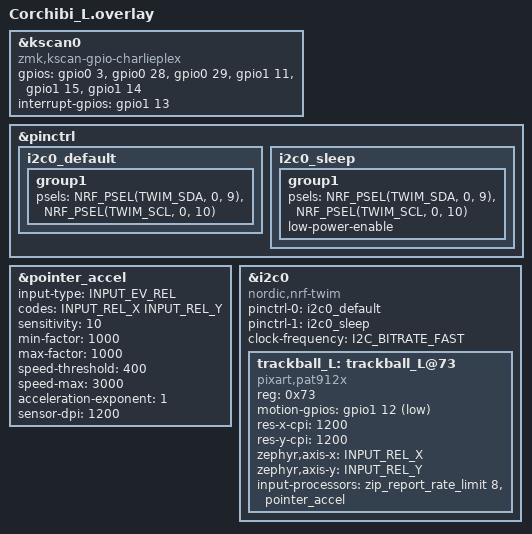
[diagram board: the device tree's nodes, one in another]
#include "corchibi.dtsi"
#include <dt-bindings/pinctrl/nrf-pinctrl.h>
#include <dt-bindings/zmk/input_transform.h>
#include <input/processors.dtsi>
#include <behaviors/input_gestures_accel.dtsi>
#include <input/processors/report_rate_limit.dtsi>

&kscan0 {
    compatible = "zmk,kscan-gpio-charlieplex";
    gpios
        = <&gpio0 3 (GPIO_ACTIVE_HIGH)>
        , <&gpio0 28 (GPIO_ACTIVE_HIGH)>
        , <&gpio0 29 (GPIO_ACTIVE_HIGH)>
        , <&gpio1 11 (GPIO_ACTIVE_HIGH)>
        , <&gpio1 15 (GPIO_ACTIVE_HIGH)>
        , <&gpio1 14 (GPIO_ACTIVE_HIGH)>
        ;
    interrupt-gpios = <&gpio1 13 (GPIO_ACTIVE_HIGH | GPIO_PULL_DOWN)>;
};

&pinctrl {
    i2c0_default: i2c0_default {
        group1 {
            psels = <NRF_PSEL(TWIM_SDA, 0, 9)>,
                    <NRF_PSEL(TWIM_SCL, 0, 10)>;
        };
    };

    i2c0_sleep: i2c0_sleep {
        group1 {
            psels = <NRF_PSEL(TWIM_SDA, 0, 9)>,
                    <NRF_PSEL(TWIM_SCL, 0, 10)>;
            low-power-enable;
        };
    };
};

&pointer_accel {
    input-type = <INPUT_EV_REL>;
    codes = <INPUT_REL_X INPUT_REL_Y>;
    sensitivity = <10>; 
    min-factor = <1000>; 
    max-factor = <1000>; 
    speed-threshold = <400>;   
    speed-max = <3000>;        
    acceleration-exponent = <1>; 
    sensor-dpi = <1200>;       
};

&i2c0 {
    status = "okay";
    compatible = "nordic,nrf-twim";
    pinctrl-0 = <&i2c0_default>;
    pinctrl-1 = <&i2c0_sleep>;
    pinctrl-names = "default", "sleep";
    clock-frequency = <I2C_BITRATE_FAST>;

    #address-cells = <1>;
    #size-cells = <0>;

    /* アドレスをRと同じ 0x73 に修正 */
    trackball_L: trackball_L@73 {
        compatible = "pixart,pat912x";
        reg = <0x73>;
        status = "okay";
        motion-gpios = <&gpio1 12 (GPIO_ACTIVE_LOW | GPIO_PULL_UP)>;
        res-x-cpi = <1200>;
        res-y-cpi = <1200>;
        zephyr,axis-x = <INPUT_REL_X>;
        zephyr,axis-y = <INPUT_REL_Y>;
        
        /* L側で直接1/100感度とレート制限を処理してからRへ送る */
        input-processors = 
            <&zip_report_rate_limit 8>,
            <&pointer_accel>;
    };
};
